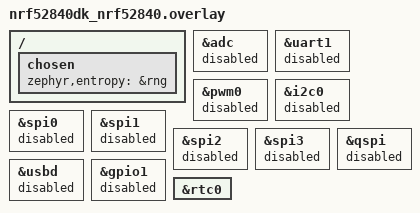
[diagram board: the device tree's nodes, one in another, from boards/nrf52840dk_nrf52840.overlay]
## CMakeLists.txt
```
#
# Copyright (c) 2020 Nordic Semiconductor ASA
#
# SPDX-License-Identifier: LicenseRef-Nordic-5-Clause
#
cmake_minimum_required(VERSION 3.20.0)

find_package(Zephyr REQUIRED HINTS $ENV{ZEPHYR_BASE})

project(openthread_coap_client)

# NORDIC SDK APP START
target_sources(app PRIVATE src/coap_client.c
			   src/coap_client_utils.c)

target_include_directories(app PUBLIC ../coap_server/interface)
# NORDIC SDK APP END

target_sources_ifdef(CONFIG_BT_NUS app PRIVATE src/ble_utils.c)
```

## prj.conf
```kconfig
#
# Copyright (c) 2020 Nordic Semiconductor
#
# SPDX-License-Identifier: LicenseRef-Nordic-5-Clause
#

# nRF board library
CONFIG_DK_LIBRARY=y

# Enable CoAP utils and CoAP protocol
CONFIG_COAP_UTILS=y
CONFIG_DTLS

# Configure sample logging setting
CONFIG_LOG=y
CONFIG_COAP_CLIENT_LOG_LEVEL_DBG=y
CONFIG_COAP_CLIENT_UTILS_LOG_LEVEL_DBG=y
CONFIG_COAP_UTILS_LOG_LEVEL_DBG=y
CONFIG_OPENTHREAD_LOG_LEVEL_NOTE=y
CONFIG_OPENTHREAD_DEBUG=y

# Adjust log strdup settings

# Generic networking options
CONFIG_NETWORKING=y

# L2 OpenThread enabling
CONFIG_NET_L2_OPENTHREAD=y

# Network shell
CONFIG_SHELL=y
CONFIG_OPENTHREAD_SHELL=y
CONFIG_SHELL_ARGC_MAX=26
CONFIG_SHELL_CMD_BUFF_SIZE=416

# Network sockets
CONFIG_NET_SOCKETS=y
CONFIG_NET_SOCKETS_POSIX_NAMES=y
CONFIG_NET_SOCKETS_POLL_MAX=4

# Same network Master Key for client and server
CONFIG_OPENTHREAD_NETWORKKEY="00:11:22:33:44:55:66:77:88:99:aa:bb:cc:dd:ee:ff"

CONFIG_ASSERT=y
CONFIG_ASSERT_NO_COND_INFO=y
CONFIG_MBEDTLS_SHA1_C=n
CONFIG_FPU=y

#Other OpenThread settings

CONFIG_OPENTHREAD_DNS_CLIENT=y
CONFIG_OPENTHREAD_SLAAC=y
CONFIG_NET_IF_UNICAST_IPV6_ADDR_COUNT=6

#Peripheral settings
CONFIG_COUNTER=y
CONFIG_COUNTER_RTC2=y
CONFIG_ISR_STACK_SIZE=2048
CONFIG_MAIN_STACK_SIZE=2560
CONFIG_SYSTEM_WORKQUEUE_STACK_SIZE= 2560

#Thread/stack debug settings
CONFIG_THREAD_ANALYZER=y
CONFIG_THREAD_ANALYZER_AUTO=n
CONFIG_THREAD_ANALYZER_ISR_STACK_USAGE=y
CONFIG_THREAD_ANALYZER_USE_LOG=y
CONFIG_THREAD_NAME=n
```

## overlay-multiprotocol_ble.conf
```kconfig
#
# Copyright (c) 2020 Nordic Semiconductor
#
# SPDX-License-Identifier: LicenseRef-Nordic-5-Clause
#

# Enable and configure Bluetooth LE
CONFIG_BT=y
CONFIG_BT_SMP=y
CONFIG_BT_PERIPHERAL=y
CONFIG_BT_DEVICE_NAME="NUS_CoAP_client"
CONFIG_BT_DEVICE_APPEARANCE=833

# Increase stack
CONFIG_SYSTEM_WORKQUEUE_STACK_SIZE=2144

# Enable the NUS service
CONFIG_BT_NUS=y

# Enable bonding
CONFIG_BT_SETTINGS=y

# Configure sample logging setting
CONFIG_BLE_UTILS_LOG_LEVEL_DBG=y
```

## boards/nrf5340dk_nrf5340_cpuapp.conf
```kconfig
#
# Copyright (c) 2021 Nordic Semiconductor
#
# SPDX-License-Identifier: LicenseRef-Nordic-5-Clause
#

# Default PRNG entropy for nRF53 Series devices is CSPRNG CC312
# which for that purpose is too slow yet
# Use Xoroshiro128+ as PRNG
CONFIG_XOROSHIRO_RANDOM_GENERATOR=y
```

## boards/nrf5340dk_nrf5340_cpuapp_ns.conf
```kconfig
#
# Copyright (c) 2021 Nordic Semiconductor
#
# SPDX-License-Identifier: LicenseRef-Nordic-5-Clause
#

# Enable Trusted Firmware M
CONFIG_BUILD_WITH_TFM=y
CONFIG_OPENTHREAD_CRYPTO_PSA=y
```

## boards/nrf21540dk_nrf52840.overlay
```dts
/* Copyright (c) 2020 Nordic Semiconductor ASA
 *
 * SPDX-License-Identifier: LicenseRef-Nordic-5-Clause
 */

/* Default Zephyr configuration already provides GPIO support for FEM. */

/ {
	/*
	* In some default configurations within the nRF Connect SDK,
	* e.g. on nRF52840, the chosen zephyr,entropy node is &cryptocell.
	* This devicetree overlay ensures that default is overridden wherever it
	* is set, as this application uses the RNG node for entropy exclusively.
	*/
	chosen {
		zephyr,entropy = &rng;
	};
};
&adc {
	status = "disabled";
};
&uart1 {
	status = "disabled";
};
&pwm0 {
	status = "disabled";
};
&i2c0 {
	status = "disabled";
};
&spi0 {
	status = "disabled";
};
&spi1 {
	status = "disabled";
};
&spi2 {
	status = "disabled";
};
&spi3 {
	status = "disabled";
};
&qspi {
	status = "disabled";
};
&usbd {
	status = "disabled";
};
```

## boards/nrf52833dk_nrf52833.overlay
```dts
/* Copyright (c) 2021 Nordic Semiconductor ASA
 *
 * SPDX-License-Identifier: LicenseRef-Nordic-5-Clause
 */


&adc {
	status = "disabled";
};
&uart1 {
	status = "disabled";
};
&pwm0 {
	status = "disabled";
};
&i2c0 {
	status = "disabled";
};
&spi0 {
	status = "disabled";
};
&spi1 {
	status = "disabled";
};
&spi2 {
	status = "disabled";
};
&spi3 {
	status = "disabled";
};
&usbd {
	status = "disabled";
};
&gpio1 {
	status = "disabled";
};
```

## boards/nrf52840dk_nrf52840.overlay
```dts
/* Copyright (c) 2020 Nordic Semiconductor ASA
 *
 * SPDX-License-Identifier: LicenseRef-Nordic-5-Clause
 */

/ {
	/*
	* In some default configurations within the nRF Connect SDK,
	* e.g. on nRF52840, the chosen zephyr,entropy node is &cryptocell.
	* This devicetree overlay ensures that default is overridden wherever it
	* is set, as this application uses the RNG node for entropy exclusively.
	*/
	chosen {
		zephyr,entropy = &rng;
	};
};
&adc {
	status = "disabled";
};
&uart1 {
	status = "disabled";
};
&pwm0 {
	status = "disabled";
};
&i2c0 {
	status = "disabled";
};
&spi0 {
	status = "disabled";
};
&spi1 {
	status = "disabled";
};
&spi2 {
	status = "disabled";
};
&spi3 {
	status = "disabled";
};
&qspi {
	status = "disabled";
};
&usbd {
	status = "disabled";
};
&gpio1 {
	status = "disabled";
};

&rtc0 {
	status = "ok";
};
```

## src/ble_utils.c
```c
/*
 * Copyright (c) 2020 Nordic Semiconductor ASA
 *
 * SPDX-License-Identifier: LicenseRef-Nordic-5-Clause
 */

#include <zephyr/kernel.h>
#include <zephyr/bluetooth/gatt.h>
#include <zephyr/bluetooth/hci.h>
#include <zephyr/bluetooth/uuid.h>
#include <zephyr/logging/log.h>
#include <zephyr/settings/settings.h>

#include "ble_utils.h"

LOG_MODULE_REGISTER(ble_utils, CONFIG_BLE_UTILS_LOG_LEVEL);

#define DEVICE_NAME CONFIG_BT_DEVICE_NAME
#define DEVICE_NAME_LEN (sizeof(DEVICE_NAME) - 1)

static void connected(struct bt_conn *conn, uint8_t err);
static void disconnected(struct bt_conn *conn, uint8_t reason);
static void auth_passkey_display(struct bt_conn *conn, unsigned int passkey);
static void auth_cancel(struct bt_conn *conn);
static void pairing_complete(struct bt_conn *conn, bool bonded);
static void pairing_failed(struct bt_conn *conn, enum bt_security_err reason);
static void __attribute__((unused))
security_changed(struct bt_conn *conn, bt_security_t level,
		 enum bt_security_err err);

static struct bt_conn_auth_cb conn_auth_callbacks = {
	.passkey_display = auth_passkey_display,
	.cancel = auth_cancel,
};

static struct bt_conn_auth_info_cb conn_auth_info_callbacks = {
	.pairing_complete = pairing_complete,
	.pairing_failed = pairing_failed
};

static struct bt_conn_cb conn_callbacks = {
	.connected = connected,
	.disconnected = disconnected,
	COND_CODE_1(CONFIG_BT_SMP, (.security_changed = security_changed), ())
};

static const struct bt_data ad[] = {
	BT_DATA_BYTES(BT_DATA_FLAGS, (BT_LE_AD_GENERAL | BT_LE_AD_NO_BREDR)),
	BT_DATA(BT_DATA_NAME_COMPLETE, DEVICE_NAME, DEVICE_NAME_LEN),
};

static const struct bt_data sd[] = {
	BT_DATA_BYTES(BT_DATA_UUID128_ALL, BT_UUID_NUS_VAL),
};

static struct k_work on_connect_work;
static struct k_work on_disconnect_work;

static struct bt_conn *current_conn;

static void connected(struct bt_conn *conn, uint8_t err)
{
	if (err) {
		LOG_ERR("Connection failed (err %u)", err);
		return;
	}

	LOG_INF("Connected");
	current_conn = bt_conn_ref(conn);

	k_work_submit(&on_connect_work);
}

static void disconnected(struct bt_conn *conn, uint8_t reason)
{
	LOG_INF("Disconnected (reason %u)", reason);

	if (current_conn) {
		bt_conn_unref(current_conn);
		current_conn = NULL;

		k_work_submit(&on_disconnect_work);
	}
}

static char *ble_addr(struct bt_conn *conn)
{
	static char addr[BT_ADDR_LE_STR_LEN];

	bt_addr_le_to_str(bt_conn_get_dst(conn), addr, sizeof(addr));

	return addr;
}

static void __attribute__((unused))
security_changed(struct bt_conn *conn, bt_security_t level,
		 enum bt_security_err err)
{
	char *addr = ble_addr(conn);

	if (!err) {
		LOG_INF("Security changed: %s level %u", addr, level);
	} else {
		LOG_INF("Security failed: %s level %u err %d", addr, level, err);
	}
}

static void auth_passkey_display(struct bt_conn *conn, unsigned int passkey)
{
	char *addr = ble_addr(conn);

	LOG_INF("Passkey for %s: %06u", addr, passkey);
}

static void auth_cancel(struct bt_conn *conn)
{
	char *addr = ble_addr(conn);

	LOG_INF("Pairing cancelled: %s", addr);
}

static void pairing_complete(struct bt_conn *conn, bool bonded)
{
	char *addr = ble_addr(conn);

	LOG_INF("Pairing completed: %s, bonded: %d", addr, bonded);
}

static void pairing_failed(struct bt_conn *conn, enum bt_security_err reason)
{
	char *addr = ble_addr(conn);

	LOG_INF("Pairing failed conn: %s, reason %d", addr, reason);
}

int ble_utils_init(struct bt_nus_cb *nus_clbs, ble_connection_cb_t on_connect,
		   ble_disconnection_cb_t on_disconnect)
{
	int ret;

	k_work_init(&on_connect_work, on_connect);
	k_work_init(&on_disconnect_work, on_disconnect);

	bt_conn_cb_register(&conn_callbacks);

	if (IS_ENABLED(CONFIG_BT_SMP)) {
		ret = bt_conn_auth_cb_register(&conn_auth_callbacks);
		if (ret) {
			LOG_ERR("Failed to register authorization callbacks.");
			goto end;
		}

		ret = bt_conn_auth_info_cb_register(&conn_auth_info_callbacks);
		if (ret) {
			LOG_ERR("Failed to register authorization info callbacks.");
			goto end;
		}
	}

	ret = bt_enable(NULL);
	if (ret) {
		LOG_ERR("Bluetooth initialization failed (error: %d)", ret);
		goto end;
	}

	LOG_INF("Bluetooth initialized");

	if (IS_ENABLED(CONFIG_SETTINGS)) {
		settings_load();
	}

	ret = bt_nus_init(nus_clbs);
	if (ret) {
		LOG_ERR("Failed to initialize UART service (error: %d)", ret);
		goto end;
	}

	ret = bt_le_adv_start(BT_LE_ADV_CONN, ad, ARRAY_SIZE(ad), sd,
			      ARRAY_SIZE(sd));
	if (ret) {
		LOG_ERR("Advertising failed to start (error: %d)", ret);
		goto end;
	}

end:
	return ret;
}
```

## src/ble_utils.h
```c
/**
 * @file
 * @defgroup ble_utils Bluetooth LE utilities API
 * @{
 */

/*
 * Copyright (c) 2020 Nordic Semiconductor ASA
 *
 * SPDX-License-Identifier: LicenseRef-Nordic-5-Clause
 */

#ifndef __BLE_UTILS_H__
#define __BLE_UTILS_H__

#include <bluetooth/services/nus.h>

/** @brief Type indicates function called when Bluetooth LE connection
 *         is established.
 *
 * @param[in] item pointer to work item.
 */
typedef void (*ble_connection_cb_t)(struct k_work *item);

/** @brief Type indicates function called when Bluetooth LE connection is ended.
 *
 * @param[in] item pointer to work item.
 */
typedef void (*ble_disconnection_cb_t)(struct k_work *item);

/** @brief Initialize CoAP utilities.
 *
 * @param[in] on_nus_received function to call when NUS receives message
 * @param[in] on_nus_send     function to call when NUS sends message
 * @param[in] on_connect      function to call when Bluetooth LE connection
 *                            is established
 * @param[in] on_disconnect   function to call when Bluetooth LE connection
 *                            is ended
 * @retval 0    On success.
 * @retval != 0 On failure.
 */
int ble_utils_init(struct bt_nus_cb *nus_clbs,
		   ble_connection_cb_t on_connect,
		   ble_disconnection_cb_t on_disconnect);

#endif

/**
 * @}
 */
```

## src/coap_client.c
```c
/*
 * Copyright (c) 2020 Nordic Semiconductor ASA
 *
 * SPDX-License-Identifier: LicenseRef-Nordic-5-Clause
 */

#include <zephyr/kernel.h>
#include <dk_buttons_and_leds.h>
#include <zephyr/logging/log.h>
#include <ram_pwrdn.h>
#include <zephyr/device.h>
#include <zephyr/pm/device.h>

#include <zephyr/drivers/counter.h>
#include <zephyr/drivers/i2c.h>

#include "coap_client_utils.h"

LOG_MODULE_DECLARE(coap_client_utils, CONFIG_COAP_CLIENT_UTILS_LOG_LEVEL);

#define OT_CONNECTION_LED DK_LED1
#define COUNTER_LED DK_LED2
#define MTD_SED_LED DK_LED3

#define ALARM_DELAY 1000000 /*1 second, units for function is usec*/
#define ALARM_CHANNEL 0

/*Variables for storing sensor data*/
static uint16_t temperature;
static uint16_t humidity;

static bool isLedOn = 0;

static void on_ot_connect(struct k_work *item)
{
	ARG_UNUSED(item);

	dk_set_led_on(OT_CONNECTION_LED);
}

static void on_ot_disconnect(struct k_work *item)
{
	ARG_UNUSED(item);

	dk_set_led_off(OT_CONNECTION_LED);
}

static void on_mtd_mode_toggle(uint32_t med)
{
#if IS_ENABLED(CONFIG_PM_DEVICE)
	const struct device *cons = DEVICE_DT_GET(DT_CHOSEN(zephyr_console));

	if (!device_is_ready(cons)) {
		return;
	}

	if (med) {
		pm_device_action_run(cons, PM_DEVICE_ACTION_RESUME);
	} else {
		pm_device_action_run(cons, PM_DEVICE_ACTION_SUSPEND);
	}
#endif
	dk_set_led(MTD_SED_LED, med);
}

static void on_button_changed(uint32_t button_state, uint32_t has_changed)
{
	uint32_t buttons = button_state & has_changed;

	if (buttons & DK_BTN1_MSK) {
		coap_client_send_sensor_data(temperature, humidity);
	}

	if (buttons & DK_BTN2_MSK) {
		printk("Nothing going on here");
	}

	if (buttons & DK_BTN3_MSK) {
		coap_client_toggle_minimal_sleepy_end_device();
	}

	if (buttons & DK_BTN4_MSK) {
		coap_client_send_provisioning_request();
	}
}

static counter_top_callback_t submit_read_sensor_work (const struct device *dev, void *user_data){
	ARG_UNUSED(user_data);
	//printk("countering every second!\n");
	dk_set_led(COUNTER_LED, !isLedOn); 
	isLedOn = !isLedOn;

	if (isProvisioned()){
		coap_client_send_sensor_data(temperature, humidity);
	}
}

void main(void)
{
	int ret;

	LOG_INF("Start CoAP-client sample");
	printk("Start CoAP-client sample");

	if (IS_ENABLED(CONFIG_RAM_POWER_DOWN_LIBRARY)) {
		power_down_unused_ram();
	}

	ret = dk_buttons_init(on_button_changed);
	if (ret) {
		LOG_ERR("Cannot init buttons (error: %d)", ret);
		return;
	}

	ret = dk_leds_init();
	if (ret) {
		LOG_ERR("Cannot init leds, (error: %d)", ret);
		return;
	}

	const struct device* rtc_dev = DEVICE_DT_GET(DT_NODELABEL(rtc2));
	counter_stop(rtc_dev);
	struct counter_top_cfg counter_cfg;
	counter_cfg.ticks = counter_us_to_ticks(rtc_dev, 5*ALARM_DELAY);
	counter_cfg.callback = submit_read_sensor_work;
	counter_cfg.user_data = &counter_cfg;
	ret = counter_set_top_value(rtc_dev, &counter_cfg);


	if (-EINVAL == ret) {
		printk("Alarm settings invalid\n");
	} else if (-ENOTSUP == ret) {
		printk("Alarm setting request not supported\n");
	} else if (ret != 0) {
		printk("Error\n");
	}

	coap_client_utils_init(on_ot_connect, on_ot_disconnect,
			       on_mtd_mode_toggle);

	while (!isProvisioned()){
		coap_client_send_provisioning_request();
		printk("waiting for provisioning");
		k_sleep(K_SECONDS(10));
	}
	counter_start(rtc_dev);
}
```

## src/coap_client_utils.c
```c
/*
 * Copyright (c) 2020 Nordic Semiconductor ASA
 *
 * SPDX-License-Identifier: LicenseRef-Nordic-5-Clause
 */

#include <zephyr/kernel.h>

#include <net/coap_utils.h>
#include <zephyr/logging/log.h>
#include <zephyr/net/openthread.h>
#include <zephyr/net/socket.h>
#include <openthread/thread.h>

#include <zephyr/debug/thread_analyzer.h>

#include "coap_server_client_interface.h"
#include "coap_client_utils.h"

LOG_MODULE_REGISTER(coap_client_utils, CONFIG_COAP_CLIENT_UTILS_LOG_LEVEL);

#define RESPONSE_POLL_PERIOD 100

static uint32_t poll_period;

static bool is_connected;

// static struct k_work send_sensor_data_work;
static struct k_work toggle_MTD_SED_work;
static struct k_work on_connect_work;
static struct k_work on_disconnect_work;

//Testing for implementing k_work object as a member of a parent struct
//Ease passing of data to the function
//Contains k_work object inside as well

static struct work_var_container provisioning_container;
static struct work_sensor_container sensor_data_container;

mtd_mode_toggle_cb_t on_mtd_mode_toggle;

/* Options supported by the server */
static const char *const node_option[] = { NODE1_URI_PATH, NULL };
static const char *const provisioning_option[] = { PROVISIONING_URI_PATH, NULL };

/* Thread multicast mesh local address */
static struct sockaddr_in6 multicast_local_addr = {
	.sin6_family = AF_INET6,
	.sin6_port = htons(COAP_PORT),
	.sin6_addr.s6_addr = { 0xff, 0x03, 0x00, 0x00, 0x00, 0x00, 0x00, 0x00,
			       0x00, 0x00, 0x00, 0x00, 0x00, 0x00, 0x00, 0x01 },
	.sin6_scope_id = 0U
};

/* Variable for storing server address acquiring in provisioning handshake */
static char unique_local_addr_str[INET6_ADDRSTRLEN] = {0};
static struct sockaddr_in6 unique_local_addr = {
	.sin6_family = AF_INET6,
	.sin6_port = htons(COAP_PORT),
	.sin6_addr.s6_addr = {0, },
	.sin6_scope_id = 0U
};

static bool is_mtd_in_med_mode(otInstance *instance)
{
	return otThreadGetLinkMode(instance).mRxOnWhenIdle;
}

static void poll_period_response_set(void)
{
	otError error;

	otInstance *instance = openthread_get_default_instance();

	if (is_mtd_in_med_mode(instance)) {
		return;
	}

	if (!poll_period) {
		poll_period = otLinkGetPollPeriod(instance);

		error = otLinkSetPollPeriod(instance, RESPONSE_POLL_PERIOD);
		__ASSERT(error == OT_ERROR_NONE, "Failed to set pool period");

		LOG_INF("Poll Period: %dms set", RESPONSE_POLL_PERIOD);
	}
}

static void poll_period_restore(void)
{
	otError error;
	otInstance *instance = openthread_get_default_instance();

	if (is_mtd_in_med_mode(instance)) {
		return;
	}

	if (poll_period) {
		error = otLinkSetPollPeriod(instance, poll_period);
		__ASSERT_NO_MSG(error == OT_ERROR_NONE);

		LOG_INF("Poll Period: %dms restored", poll_period);
		poll_period = 0;
	}
}

static int on_provisioning_reply(const struct coap_packet *response,
				 struct coap_reply *reply,
				 const struct sockaddr *from)
{
	int ret = 0;
	const uint8_t *payload;
	uint16_t payload_size = 0u;
	
	//Testing for printing out IPaddr from OT
	// otInstance *instance = openthread_get_default_instance();
	// void * ipaddr_ot = otThreadGetMeshLocalEid(instance);
	// int ipaddr_size = sizeof(otIp6Address);
	// LOG_HEXDUMP_INF(ipaddr_ot, ipaddr_size, "IP address");

	ARG_UNUSED(reply);
	ARG_UNUSED(from);

	payload = coap_packet_get_payload(response, &payload_size);

	if (payload == NULL) {
		LOG_ERR("No data received");
		ret = -EINVAL;
		goto exit;
	}
	
	// LOG_INF("Payload received: %s", payload);
	// LOG_INF("Payload size: %d", payload_size);

	//Convert the payload from ASCII encoded characters into literal integers
	//Process is performed in 2 byte char fragments turning into 1 byte uint8:

	// if (payload_size != 32) {
	// 	LOG_ERR("Questionable data format received");
	// 	ret = -EINVAL;
	// 	goto exit;
	// }

	// uint8_t ipaddr_int [16];
	// for(int i = 0; i < (payload_size/2); i++){
	// 	char* unused_ptr;
	// 	char payload_fragment [2];

	// 	memcpy(&payload_fragment, payload+(2*i), 2);
	// 	ipaddr_int[i] = strtol(payload_fragment, &unused_ptr, 16);
	// }

	// LOG_HEXDUMP_INF(ipaddr_int, 16, "Fully converted IP fragment");
	if (!inet_pton(AF_INET6, payload, &unique_local_addr.sin6_addr)){
		LOG_ERR("Received data is not IPv6 address: %d", errno);
		ret = -errno;
		goto exit;
	}
	memcpy(unique_local_addr_str, payload, payload_size);

	LOG_INF("Received peer address: %s", unique_local_addr_str);

exit:
	if (IS_ENABLED(CONFIG_OPENTHREAD_MTD_SED)) {
		poll_period_restore();
	}

	return ret;
}

static void send_sensor_data(struct k_work *item)
{
	char payload []= "25.0/40/good";

	ARG_UNUSED(item);

	if (unique_local_addr.sin6_addr.s6_addr16[0] == 0) {
		LOG_WRN("Peer address not set. Activate 'provisioning' option "
			"on the server side");
		return;
	}

	LOG_INF("Send 'light' request to: %s", unique_local_addr_str);
	//thread_analyzer_print();
	coap_send_request(COAP_METHOD_PUT,
			  (const struct sockaddr *)&unique_local_addr,
			  node_option, payload, sizeof(payload), NULL);
}

static void send_provisioning_request(struct k_work *item)
{
	if (IS_ENABLED(CONFIG_OPENTHREAD_MTD_SED)) {
		/* decrease the polling period for higher responsiveness */
		poll_period_response_set();
	}
	//LOG_INF("Testing data before CONTAINER_OF method: %s", provisioning_container.testing_data);

	//Testing for container of functionality
	// struct work_var_container * container_ptr = CONTAINER_OF(item, struct work_var_container, work_obj);
	// LOG_INF("Testing data originally: %s", container_ptr->testing_data);
	// container_ptr->testing_data = "New value";	
	// LOG_INF("Testing data changed to: %s", container_ptr->testing_data);
	// LOG_INF("Testing data after CONTAINER_OF method: %s", provisioning_container.testing_data);
	// LOG_INF("Provisioning work address that should be used: %x", provisioning_container.work_obj);
	// LOG_INF("Provisioning work address provided as argument: %x", item);
	// LOG_INF("Original struct address: %x", &provisioning_container);
	// LOG_INF("CONTAINER_OF struct address: %x", container_ptr);	

	LOG_INF("Send 'provisioning' request");
	coap_send_request(COAP_METHOD_GET,
			  (const struct sockaddr *)&multicast_local_addr,
			  provisioning_option, NULL, 0u, on_provisioning_reply);
}

static void toggle_minimal_sleepy_end_device(struct k_work *item)
{
	otError error;
	otLinkModeConfig mode;
	struct openthread_context *context = openthread_get_default_context();

	__ASSERT_NO_MSG(context != NULL);

	openthread_api_mutex_lock(context);
	mode = otThreadGetLinkMode(context->instance);
	mode.mRxOnWhenIdle = !mode.mRxOnWhenIdle;
	error = otThreadSetLinkMode(context->instance, mode);
	openthread_api_mutex_unlock(context);

	if (error != OT_ERROR_NONE) {
		LOG_ERR("Failed to set MLE link mode configuration");
	} else {
		on_mtd_mode_toggle(mode.mRxOnWhenIdle);
	}
}

static void update_device_state(void)
{
	struct otInstance *instance = openthread_get_default_instance();
	otLinkModeConfig mode = otThreadGetLinkMode(instance);
	on_mtd_mode_toggle(mode.mRxOnWhenIdle);
}

static void on_thread_state_changed(uint32_t flags, void *context)
{
	struct openthread_context *ot_context = context;

	if (flags & OT_CHANGED_THREAD_ROLE) {
		switch (otThreadGetDeviceRole(ot_context->instance)) {
		case OT_DEVICE_ROLE_CHILD:
		case OT_DEVICE_ROLE_ROUTER:
		case OT_DEVICE_ROLE_LEADER:
			k_work_submit(&on_connect_work);
			is_connected = true;
			break;

		case OT_DEVICE_ROLE_DISABLED:
		case OT_DEVICE_ROLE_DETACHED:
		default:
			k_work_submit(&on_disconnect_work);
			is_connected = false;
			break;
		}
	}
}

static void submit_work_if_connected(struct k_work *work)
{
	if (is_connected) {
		k_work_submit(work);
	} else {
		LOG_INF("Connection is broken");
	}
}

bool isProvisioned(){
	return unique_local_addr_str[0];
}

void coap_client_utils_init(ot_connection_cb_t on_connect,
			    ot_disconnection_cb_t on_disconnect,
			    mtd_mode_toggle_cb_t on_toggle)
{
	on_mtd_mode_toggle = on_toggle;

	coap_init(AF_INET6, NULL);

	k_work_init(&on_connect_work, on_connect);
	k_work_init(&on_disconnect_work, on_disconnect);
	k_work_init(&sensor_data_container.work_obj, send_sensor_data);
	k_work_init(&provisioning_container.work_obj, send_provisioning_request);

	openthread_set_state_changed_cb(on_thread_state_changed);
	openthread_start(openthread_get_default_context());

	if (IS_ENABLED(CONFIG_OPENTHREAD_MTD_SED)) {
		k_work_init(&toggle_MTD_SED_work,
			    toggle_minimal_sleepy_end_device);
		update_device_state();
	}
}

void coap_client_send_sensor_data(uint16_t temperature_data, uint16_t humidity_data)
{
	submit_work_if_connected(&sensor_data_container.work_obj);
}

void coap_client_send_provisioning_request(void)
{
	submit_work_if_connected(&provisioning_container.work_obj);
}

void coap_client_toggle_minimal_sleepy_end_device(void)
{
	if (IS_ENABLED(CONFIG_OPENTHREAD_MTD_SED)) {
		k_work_submit(&toggle_MTD_SED_work);
	}
}
```

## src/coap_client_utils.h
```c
/**
 * @file
 * @defgroup coap_client_utils API for coap_client_* samples
 * @{
 */

/*
 * Copyright (c) 2020 Nordic Semiconductor ASA
 *
 * SPDX-License-Identifier: LicenseRef-Nordic-5-Clause
 */

#ifndef __COAP_CLIENT_UTILS_H__
#define __COAP_CLIENT_UTILS_H__

/** @brief Struct for implementing k_work object as a member of a parent struct 
 * to enable passing of data to the function
 *
 *  
 */

struct work_var_container{
	struct k_work 	work_obj; 		/*Store the work object here*/
	char* 		testing_data;	/*Store the testing data here*/
};

struct work_sensor_container{
	struct k_work 	work_obj; 		/*Store the work object here*/
	uint16_t 		temperature;	/*Store the raw temperature data here*/
	uint16_t		humidity;		/*Store the raw humidity data here*/
};

/** @brief Type indicates function called when OpenThread connection
 *         is established.
 *
 * @param[in] item pointer to work item.
 */
typedef void (*ot_connection_cb_t)(struct k_work *item);

/** @brief Type indicates function called when OpenThread connection is ended.
 *
 * @param[in] item pointer to work item.
 */
typedef void (*ot_disconnection_cb_t)(struct k_work *item);

/** @brief Type indicates function called when the MTD modes are toggled.
 *
 * @param[in] val 1 if the MTD is in MED mode
 *                0 if the MTD is in SED mode
 */
typedef void (*mtd_mode_toggle_cb_t)(uint32_t val);

/** @brief Initialize CoAP client utilities.
 */
void coap_client_utils_init(ot_connection_cb_t on_connect,
			    ot_disconnection_cb_t on_disconnect,
			    mtd_mode_toggle_cb_t on_toggle);

/** @brief Toggle light on the CoAP server node.
 *
 * @note The CoAP server should be paired before to have an effect.
 */
void coap_client_send_sensor_data (uint16_t temperature_data, uint16_t humidity_data);


/** @brief Request for the CoAP server address to pair.
 *
 * @note Enable paring on the CoAP server to get the address.
 */
void coap_client_send_provisioning_request(void);

/** @brief Function to determine if successful provisioning was performed
 *  
 * @note Determined by checking byte-0 of IP address string, which is initialized to 0
 * After provisioning, the first byte is always set.
*/

bool isProvisioned(void);

/** @brief Toggle SED to MED and MED to SED modes.
 *
 * @note Active when the device is working as Minimal Thread Device.
 */
void coap_client_toggle_minimal_sleepy_end_device(void);

#endif

/**
 * @}
 */
```

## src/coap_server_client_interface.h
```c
/*
 * Copyright (c) 2020 Nordic Semiconductor ASA
 *
 * SPDX-License-Identifier: LicenseRef-Nordic-5-Clause
 */

#ifndef __COAP_SERVER_CLIENT_INTRFACE_H__
#define __COAP_SERVER_CLIENT_INTRFACE_H__

#define COAP_PORT 5683

#define PROVISIONING_URI_PATH "provisioning" 
#define NODE1_URI_PATH "SensorNode1" 
#define NODE2_URI_PATH "SensorNode2" 

#endif
```
